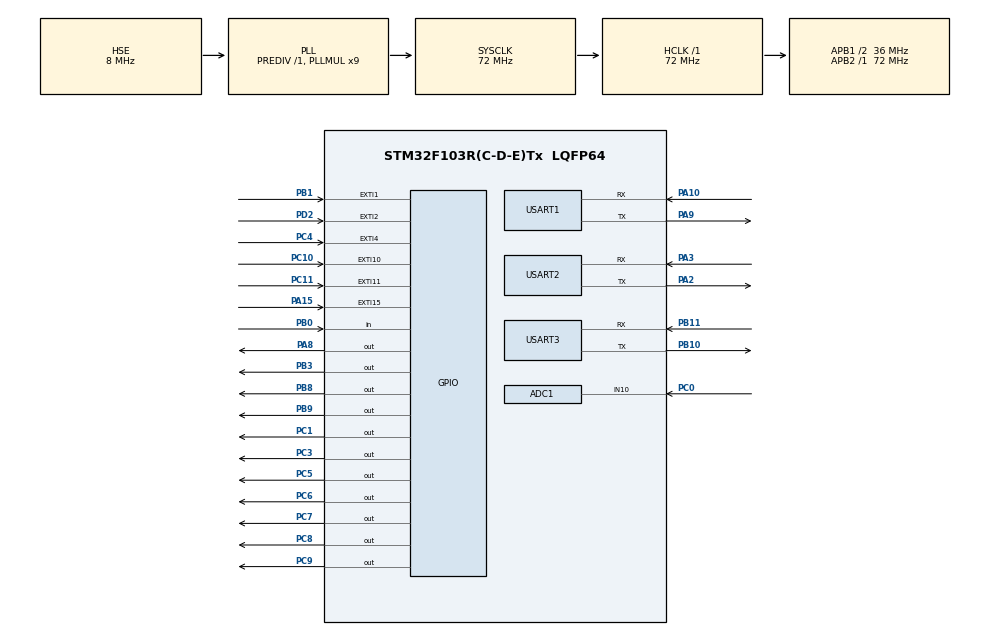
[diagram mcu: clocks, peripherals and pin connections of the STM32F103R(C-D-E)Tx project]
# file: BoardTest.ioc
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ADC1.Channel-2\#ChannelRegularConversion=ADC_CHANNEL_10
ADC1.NbrOfConversion=1
ADC1.NbrOfConversionFlag=1
ADC1.Rank-2\#ChannelRegularConversion=1
ADC1.SamplingTime-2\#ChannelRegularConversion=ADC_SAMPLETIME_13CYCLES_5
ADC1.master=1
Mcu.Family=STM32F1
Mcu.Name=STM32F103R(C-D-E)Tx
Mcu.Package=LQFP64
NVIC.EXTI15_10_IRQn=true\:0\:0\:false\:false\:true\:true\:true
NVIC.EXTI1_IRQn=true\:0\:0\:false\:false\:true\:true\:true
NVIC.EXTI2_IRQn=true\:0\:0\:false\:false\:true\:true\:true
NVIC.EXTI4_IRQn=true\:0\:0\:false\:false\:true\:true\:true
NVIC.PriorityGroup=NVIC_PRIORITYGROUP_4
NVIC.TIM3_IRQn=true\:0\:0\:false\:false\:true\:true\:true
NVIC.USART1_IRQn=true\:0\:0\:false\:false\:true\:true\:true
NVIC.USART2_IRQn=true\:0\:0\:false\:false\:true\:true\:true
NVIC.USART3_IRQn=true\:0\:0\:false\:false\:true\:true\:true
PA10.Mode=Asynchronous
PA10.Signal=USART1_RX
PA13.Mode=Serial_Wire
PA13.Signal=SYS_JTMS-SWDIO
PA14.Mode=Serial_Wire
PA14.Signal=SYS_JTCK-SWCLK
PA15.GPIO_ModeDefaultEXTI=GPIO_MODE_IT_RISING_FALLING
PA15.GPIO_PuPd=GPIO_PULLUP
PA15.Signal=GPXTI15
PA2.Mode=Asynchronous
PA2.Signal=USART2_TX
PA3.Mode=Asynchronous
PA3.Signal=USART2_RX
PA8.Signal=GPIO_Output
PA9.Mode=Asynchronous
PA9.Signal=USART1_TX
PB0.Signal=GPIO_Input
PB1.GPIO_ModeDefaultEXTI=GPIO_MODE_IT_RISING_FALLING
PB1.Signal=GPXTI1
PB10.Mode=Asynchronous
PB10.Signal=USART3_TX
PB11.Mode=Asynchronous
PB11.Signal=USART3_RX
PB3.Signal=GPIO_Output
PB8.Signal=GPIO_Output
PB9.Signal=GPIO_Output
PC0.Signal=ADCx_IN10
PC1.GPIO_PuPd=GPIO_PULLDOWN
PC1.GPIO_Speed=GPIO_SPEED_FREQ_HIGH
PC1.Signal=GPIO_Output
PC10.GPIO_ModeDefaultEXTI=GPIO_MODE_IT_RISING_FALLING
PC10.GPIO_PuPd=GPIO_PULLUP
PC10.Signal=GPXTI10
PC11.GPIO_ModeDefaultEXTI=GPIO_MODE_IT_RISING_FALLING
PC11.GPIO_PuPd=GPIO_PULLUP
PC11.Signal=GPXTI11
PC14-OSC32_IN.Mode=LSE-External-Oscillator
PC14-OSC32_IN.Signal=RCC_OSC32_IN
PC15-OSC32_OUT.Mode=LSE-External-Oscillator
PC15-OSC32_OUT.Signal=RCC_OSC32_OUT
PC3.GPIO_PuPd=GPIO_PULLDOWN
PC3.Signal=GPIO_Output
PC4.Signal=GPXTI4
PC5.GPIO_ModeDefaultOutputPP=GPIO_MODE_OUTPUT_PP
PC5.GPIO_PuPd=GPIO_NOPULL
PC5.GPIO_Speed=GPIO_SPEED_FREQ_LOW
PC5.PinState=GPIO_PIN_RESET
PC5.Signal=GPIO_Output
PC6.Signal=GPIO_Output
PC7.Signal=GPIO_Output
PC8.Signal=GPIO_Output
PC9.Signal=GPIO_Output
PD0-OSC_IN.Mode=HSE-External-Oscillator
PD0-OSC_IN.Signal=RCC_OSC_IN
PD1-OSC_OUT.Mode=HSE-External-Oscillator
PD1-OSC_OUT.Signal=RCC_OSC_OUT
PD2.GPIO_ModeDefaultEXTI=GPIO_MODE_IT_FALLING
PD2.GPIO_PuPd=GPIO_PULLUP
PD2.Signal=GPXTI2
ProjectManager.HeapSize=0x200
ProjectManager.StackSize=0x400
ProjectManager.TargetToolchain=MDK-ARM V5
RCC.ADCPresc=RCC_ADCPCLK2_DIV6
RCC.AHBFreq_Value=72000000
RCC.APB1CLKDivider=RCC_HCLK_DIV2
RCC.APB1Freq_Value=36000000
RCC.APB1TimFreq_Value=72000000
RCC.APB2Freq_Value=72000000
RCC.APB2TimFreq_Value=72000000
RCC.HCLKFreq_Value=72000000
RCC.PLLMUL=RCC_PLL_MUL9
RCC.PLLSourceVirtual=RCC_PLLSOURCE_HSE
RCC.SYSCLKFreq_VALUE=72000000
RCC.SYSCLKSource=RCC_SYSCLKSOURCE_PLLCLK
RCC.USBFreq_Value=72000000
RTC.Date=18
RTC.Format=RTC_FORMAT_BIN
RTC.Hours=16
RTC.Month=RTC_MONTH_MARCH
RTC.Seconds=1
RTC.WeekDay=RTC_WEEKDAY_WEDNESDAY
RTC.Year=50
SH.ADCx_IN10.0=ADC1_IN10,IN10
TIM3.AutoReloadPreload=TIM_AUTORELOAD_PRELOAD_ENABLE
TIM3.Period=56
TIM3.Prescaler=72
USART1.VirtualMode=VM_ASYNC
USART2.VirtualMode=VM_ASYNC
USART3.VirtualMode=VM_ASYNC
VP_RTC_VS_RTC_Activate.Mode=RTC_Enabled
VP_RTC_VS_RTC_Calendar.Mode=RTC_Calendar
VP_TIM3_VS_ClockSourceINT.Mode=Internal
board=custom

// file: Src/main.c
/* USER CODE BEGIN Header */
/**
  ******************************************************************************
  * @file           : main.c
  * @brief          : Main program body
  ******************************************************************************
  * @attention
  *
  * <h2><center>&copy; Copyright (c) 2020 STMicroelectronics.
  * All rights reserved.</center></h2>
  *
  * This software component is licensed by ST under BSD 3-Clause license,
  * the "License"; You may not use this file except in compliance with the
  * License. You may obtain a copy of the License at:
  *                        opensource.org/licenses/BSD-3-Clause
  *
  ******************************************************************************
  */
/* USER CODE END Header */

#include "main.h"
#include "adc.h"
#include "rtc.h"
#include "tim.h"
#include "usart.h"
#include "gpio.h"

/* USER CODE BEGIN Includes */
#include "board_test.h"
/* USER CODE END Includes */

void SystemClock_Config(void);

/* USER CODE BEGIN 0 */
extern TIM_HandleTypeDef htim3;
/* USER CODE END 0 */

int main(void)
{

  /* MCU Configuration--------------------------------------------------------*/

  /* Reset of all peripherals, Initializes the Flash interface and the Systick. */
  HAL_Init();

  /* Configure the system clock */
  SystemClock_Config();

  /* Initialize all configured peripherals */
  MX_GPIO_Init();
  MX_ADC1_Init();
  MX_RTC_Init();
  MX_USART1_UART_Init();
  MX_USART2_UART_Init();
  MX_TIM3_Init();
  MX_USART3_UART_Init();
  /* USER CODE BEGIN 2 */
	BaordInit();

  /* USER CODE END 2 */

  /* Infinite loop */
  while (1)
  {

    /* USER CODE BEGIN 3 */
		BoardTest();

  }
  /* USER CODE END 3 */
}

void SystemClock_Config(void)
{
  RCC_OscInitTypeDef RCC_OscInitStruct = {0};
  RCC_ClkInitTypeDef RCC_ClkInitStruct = {0};
  RCC_PeriphCLKInitTypeDef PeriphClkInit = {0};

  /** Initializes the CPU, AHB and APB busses clocks
  */
  RCC_OscInitStruct.OscillatorType = RCC_OSCILLATORTYPE_LSI|RCC_OSCILLATORTYPE_HSE;
  RCC_OscInitStruct.HSEState = RCC_HSE_ON;
  RCC_OscInitStruct.HSEPredivValue = RCC_HSE_PREDIV_DIV1;
  RCC_OscInitStruct.HSIState = RCC_HSI_ON;
  RCC_OscInitStruct.LSIState = RCC_LSI_ON;
  RCC_OscInitStruct.PLL.PLLState = RCC_PLL_ON;
  RCC_OscInitStruct.PLL.PLLSource = RCC_PLLSOURCE_HSE;
  RCC_OscInitStruct.PLL.PLLMUL = RCC_PLL_MUL9;
  if (HAL_RCC_OscConfig(&RCC_OscInitStruct) != HAL_OK)
  {
    Error_Handler();
  }
  /** Initializes the CPU, AHB and APB busses clocks
  */
  RCC_ClkInitStruct.ClockType = RCC_CLOCKTYPE_HCLK|RCC_CLOCKTYPE_SYSCLK
                              |RCC_CLOCKTYPE_PCLK1|RCC_CLOCKTYPE_PCLK2;
  RCC_ClkInitStruct.SYSCLKSource = RCC_SYSCLKSOURCE_PLLCLK;
  RCC_ClkInitStruct.AHBCLKDivider = RCC_SYSCLK_DIV1;
  RCC_ClkInitStruct.APB1CLKDivider = RCC_HCLK_DIV2;
  RCC_ClkInitStruct.APB2CLKDivider = RCC_HCLK_DIV1;

  if (HAL_RCC_ClockConfig(&RCC_ClkInitStruct, FLASH_LATENCY_2) != HAL_OK)
  {
    Error_Handler();
  }
  PeriphClkInit.PeriphClockSelection = RCC_PERIPHCLK_RTC|RCC_PERIPHCLK_ADC;
  PeriphClkInit.RTCClockSelection = RCC_RTCCLKSOURCE_LSI;
  PeriphClkInit.AdcClockSelection = RCC_ADCPCLK2_DIV6;
  if (HAL_RCCEx_PeriphCLKConfig(&PeriphClkInit) != HAL_OK)
  {
    Error_Handler();
  }
}

void Error_Handler(void)
{
}

/************************ (C) COPYRIGHT STMicroelectronics *****END OF FILE****/
